# MIMXRT1021 register map
Vendor: nxp.com; File version: 1.0
CPU: CM7 r0p1, little endian, MPU, FPU, VTOR, 4 interrupt priority bits
Registers are 32-bit, read-write, reset 0x0 unless marked. A register's access mark holds for its fields unless they carry their own. Offsets are from the block's base; [hi:lo] are bit positions; 'fields as' and 'values as' point back to an identical list.

## LPI2C1 — LPI2C
Base 0x403F0000
Same registers: LPI2C2 0x403F4000, LPI2C3 0x403F8000, LPI2C4 0x403FC000
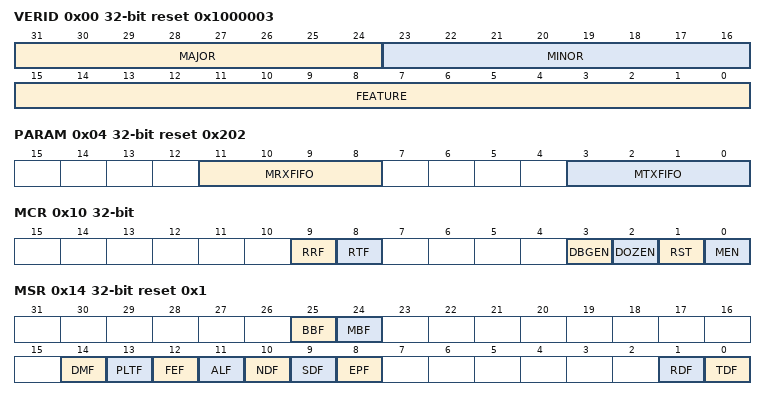
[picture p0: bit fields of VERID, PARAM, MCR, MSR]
0x00 VERID ro reset 0x1000003 — Version ID
  [31:24] MAJOR — Major Version Number
  [23:16] MINOR — Minor Version Number
  [15:0] FEATURE — Feature Specification Number
    2=MASTER_ONLY (Master only, with standard feature set); 3=MASTER_AND_SLAVE (Master and slave, with standard feature set)
0x04 PARAM ro reset 0x202 — Parameter
  [11:8] MRXFIFO — Master Receive FIFO Size
  [3:0] MTXFIFO — Master Transmit FIFO Size
0x10 MCR — Master Control
  [9] RRF — Reset Receive FIFO
    0=NO_EFFECT; 1=RESET (Receive FIFO is reset)
  [8] RTF — Reset Transmit FIFO
    0=NO_EFFECT; 1=RESET (Transmit FIFO is reset)
  [3] DBGEN — Debug Enable
    0=DISABLED (Master is disabled in debug mode); 1=ENABLED (Master is enabled in debug mode)
  [2] DOZEN — Doze mode enable
    0=ENABLED (Master is enabled in Doze mode); 1=DISABLED (Master is disabled in Doze mode)
  [1] RST — Software Reset
    0=NOT_RESET (Master logic is not reset); 1=RESET (Master logic is reset)
  [0] MEN — Master Enable
    0=DISABLED (Master logic is disabled); 1=ENABLED (Master logic is enabled)
0x14 MSR reset 0x1 — Master Status
  [25] BBF ro — Bus Busy Flag
    0=IDLE (I2C Bus is idle); 1=BUSY (I2C Bus is busy)
  [24] MBF ro — Master Busy Flag
    0=IDLE (I2C Master is idle); 1=BUSY (I2C Master is busy)
  [14] DMF write-1-clears — Data Match Flag
    0=NO_FLAG (Have not received matching data); 1=FLAG (Have received matching data)
  [13] PLTF write-1-clears — Pin Low Timeout Flag
    0=NO_FLAG (Pin low timeout has not occurred or is disabled); 1=FLAG (Pin low timeout has occurred)
  [12] FEF write-1-clears — FIFO Error Flag
    0=NO_FLAG (No error); 1=FLAG (Master sending or receiving data without a START condition)
  [11] ALF write-1-clears — Arbitration Lost Flag
    0=NO_FLAG (Master has not lost arbitration); 1=FLAG (Master has lost arbitration)
  [10] NDF write-1-clears — NACK Detect Flag
    0=NO_FLAG (Unexpected NACK was not detected); 1=FLAG (Unexpected NACK was detected)
  [9] SDF write-1-clears — STOP Detect Flag
    0=NO_FLAG (Master has not generated a STOP condition); 1=FLAG (Master has generated a STOP condition)
  [8] EPF write-1-clears — End Packet Flag
    0=NO_FLAG (Master has not generated a STOP or Repeated START condition); 1=FLAG (Master has generated a STOP or Repeated START condition)
  [1] RDF ro — Receive Data Flag
    0=DISABLED (Receive Data is not ready); 1=ENABLED (Receive data is ready)
  [0] TDF ro — Transmit Data Flag
    0=DISABLED (Transmit data is not requested); 1=ENABLED (Transmit data is requested)
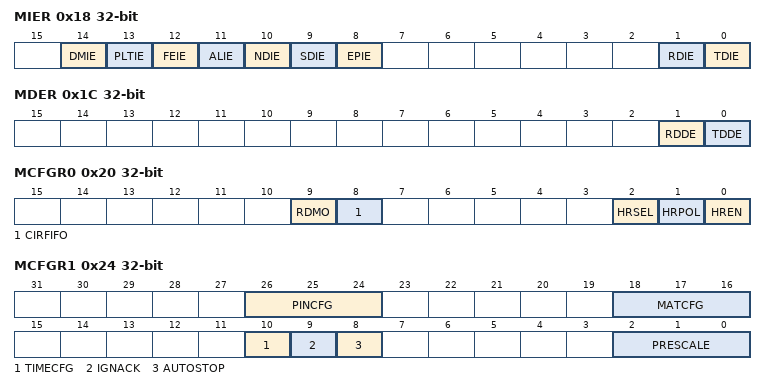
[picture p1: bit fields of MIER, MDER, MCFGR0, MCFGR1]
0x18 MIER — Master Interrupt Enable
  [14] DMIE — Data Match Interrupt Enable
    0=DISABLED; 1=ENABLED
  [13] PLTIE — Pin Low Timeout Interrupt Enable
    0=DISABLED; 1=ENABLED
  [12] FEIE — FIFO Error Interrupt Enable
    0=ENABLED; 1=DISABLED
  [11] ALIE — Arbitration Lost Interrupt Enable
    0=DISABLED; 1=ENABLED
  [10] NDIE — NACK Detect Interrupt Enable
    0=DISABLED; 1=ENABLED
  [9] SDIE — STOP Detect Interrupt Enable
    0=DISABLED; 1=ENABLED
  [8] EPIE — End Packet Interrupt Enable
    0=DISABLED; 1=ENABLED
  [1] RDIE — Receive Data Interrupt Enable
    0=DISABLED; 1=ENABLED
  [0] TDIE — Transmit Data Interrupt Enable
    0=DISABLED; 1=ENABLED
0x1C MDER — Master DMA Enable
  [1] RDDE — Receive Data DMA Enable
    0=DISABLED (DMA request is disabled); 1=ENABLED (DMA request is enabled)
  [0] TDDE — Transmit Data DMA Enable
    values as RDDE
0x20 MCFGR0 — Master Configuration 0
  [9] RDMO — Receive Data Match Only
    0=DISABLED (Received data is stored in the receive FIFO); 1=ENABLED (Received data is discarded unless the the Data Match Flag (MSR[DMF]) is set)
  [8] CIRFIFO — Circular FIFO Enable
    0=DISABLED (Circular FIFO is disabled); 1=ENABLED (Circular FIFO is enabled)
  [2] HRSEL — Host Request Select
    0=DISABLED (Host request input is pin HREQ); 1=ENABLED (Host request input is input trigger)
  [1] HRPOL — Host Request Polarity
    0=ACTIVE_LOW; 1=ACTIVE_HIGH
  [0] HREN — Host Request Enable
    0=DISABLED (Host request input is disabled); 1=ENABLED (Host request input is enabled)
0x24 MCFGR1 — Master Configuration 1
  [26:24] PINCFG — Pin Configuration
    0=OPEN_DRAIN_2_PIN (2-pin open drain mode); 1=OUTPUT_2_PIN_ONLY (2-pin output only mode (ultra-fast mode)); 2=PUSH_PULL_2_PIN (2-pin push-pull mode); 3=PUSH_PULL_4_PIN (4-pin push-pull mode); 4=OPEN_DRAIN_2_PIN_W_LPI2C_SLAVE (2-pin open drain mode with separate LPI2C slave); 5=OUTPUT_2_PIN_ONLY_W_LPI2C_SLAVE (2-pin output only mode (ultra-fast mode) with separate LPI2C slave); 6=PUSH_PULL_2_PIN_W_LPI2C_SLAVE (2-pin push-pull mode with separate LPI2C slave); 7=PUSH_PULL_4_PIN_W_LPI2C_SLAVE (4-pin push-pull mode (inverted outputs))
  [18:16] MATCFG — Match Configuration
    0=DISABLED (Match is disabled); 2=FIRST_DATA_WORD_EQUALS_MATCH0_OR_MATCH1 (Match is enabled (1st data word equals MDMR[MATCH0] OR MDMR[MATCH1])); 3=ANY_DATA_WORD_EQUALS_MATCH0_OR_MATCH1 (Match is enabled (any data word equals MDMR[MATCH0] OR MDMR[MATCH1])); 4=FIRST_DATA_WORD_MATCH0_AND_SECOND_DATA_WORD_MATCH1 (Match is enabled (1st data word equals MDMR[MATCH0] AND 2nd data word equals MDMR[MATCH1)); 5=ANY_DATA_WORD_MATCH0_NEXT_DATA_WORD_MATCH1 (Match is enabled (any data word equals MDMR[MATCH0] AND next data word equals MDMR[MATCH1)); 6=FIRST_DATA_WORD_AND_MATCH1_EQUALS_MATCH0_AND_MATCH1 (Match is enabled (1st data word AND MDMR[MATCH1] equals MDMR[MATCH0] AND MDMR[MATCH1])); 7=ANY_DATA_WORD_AND_MATCH1_EQUALS_MATCH0_AND_MATCH1 (Match is enabled (any data word AND MDMR[MATCH1] equals MDMR[MATCH0] AND MDMR[MATCH1]))
  [10] TIMECFG — Timeout Configuration
    0=IF_SCL_LOW (MSR[PLTF] sets if SCL is low for longer than the configured timeout); 1=IF_SCL_OR_SDA_LOW (MSR[PLTF] sets if either SCL or SDA is low for longer than the configured timeout)
  [9] IGNACK
    0=DISABLED (LPI2C Master receives ACK and NACK normally); 1=ENABLED (LPI2C Master treats a received NACK as if it (NACK) was an ACK)
  [8] AUTOSTOP — Automatic STOP Generation
    0=DISABLED (No effect); 1=ENABLED (STOP condition is automatically generated whenever the transmit FIFO is empty and the LPI2C master is busy)
  [2:0] PRESCALE — Prescaler
    0=DIVIDE_BY_1; 1=DIVIDE_BY_2; 2=DIVIDE_BY_4; 3=DIVIDE_BY_8; 4=DIVIDE_BY_16; 5=DIVIDE_BY_32; 6=DIVIDE_BY_64; 7=DIVIDE_BY_128
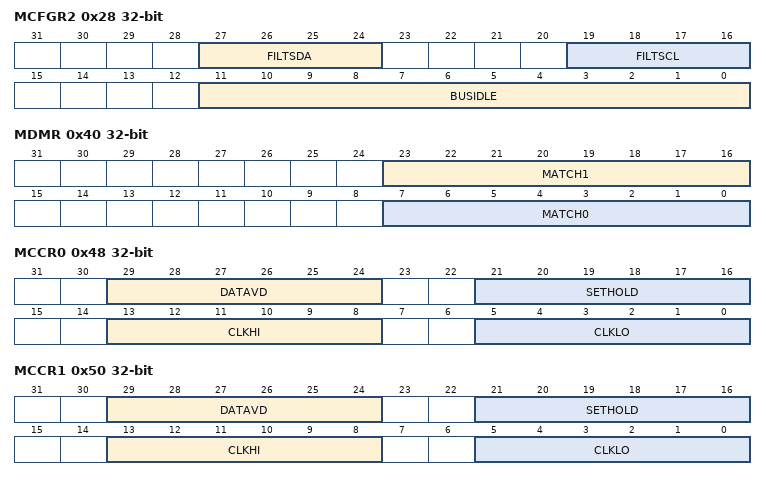
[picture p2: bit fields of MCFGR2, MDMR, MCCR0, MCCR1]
0x28 MCFGR2 — Master Configuration 2
  [27:24] FILTSDA — Glitch Filter SDA
  [19:16] FILTSCL — Glitch Filter SCL
  [11:0] BUSIDLE — Bus Idle Timeout
0x2C MCFGR3 — Master Configuration 3
  [19:8] PINLOW — Pin Low Timeout
0x40 MDMR — Master Data Match
  [23:16] MATCH1 — Match 1 Value
  [7:0] MATCH0 — Match 0 Value
0x48 MCCR0 — Master Clock Configuration 0
  [29:24] DATAVD — Data Valid Delay
  [21:16] SETHOLD — Setup Hold Delay
  [13:8] CLKHI — Clock High Period
  [5:0] CLKLO — Clock Low Period
0x50 MCCR1 — Master Clock Configuration 1
  fields as MCCR0
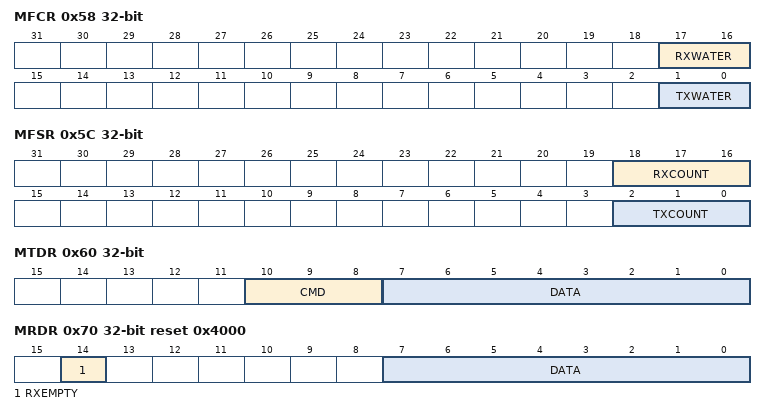
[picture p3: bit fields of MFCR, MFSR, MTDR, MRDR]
0x58 MFCR — Master FIFO Control
  [17:16] RXWATER — Receive FIFO Watermark
  [1:0] TXWATER — Transmit FIFO Watermark
0x5C MFSR ro — Master FIFO Status
  [18:16] RXCOUNT — Receive FIFO Count
  [2:0] TXCOUNT — Transmit FIFO Count
0x60 MTDR wo — Master Transmit Data
  [10:8] CMD — Command Data
    0=TRANSMIT_DATA_7_THROUGH_0 (Transmit DATA[7:0]); 1=RECEIVE_DATA_7_THROUGH_0_PLUS_ONE (Receive (DATA[7:0] + 1) bytes); 2=GENERATE_STOP_CONDITION; 3=RECEIVE_AND_DISCARD_DATA_7_THROUGH_0_PLUS_ONE (Receive and discard (DATA[7:0] + 1) bytes); 4=GENERATE_START_AND_TRANSMIT_ADDRESS_IN_DATA_7_THROUGH_0 (Generate (repeated) START and transmit address in DATA[7:0]); 5=GENERATE_START_AND_TRANSMIT_ADDRESS_IN_DATA_7_THROUGH_0_EXPECT_NACK (Generate (repeated) START and transmit address in DATA[7:0]. This transfer expects a NACK to be returned.); 6=GENERATE_START_AND_TRANSMIT_ADDRESS_IN_DATA_7_THROUGH_0_USING_HIGH_SPEED_MODE (Generate (repeated) START and transmit address in DATA[7:0] using high speed mode); 7=GENERATE_START_AND_TRANSMIT_ADDRESS_IN_DATA_7_THROUGH_0_USING_HIGH_SPEED_MODE_EXPECT_NACK (Generate (repeated) START and transmit address in DATA[7:0] using high speed mode. This transfer expects a NACK to be returned.)
  [7:0] DATA — Transmit Data
0x70 MRDR ro reset 0x4000 — Master Receive Data
  [14] RXEMPTY
    0=NOT_EMPTY (Receive FIFO is not empty); 1=EMPTY (Receive FIFO is empty)
  [7:0] DATA — Receive Data
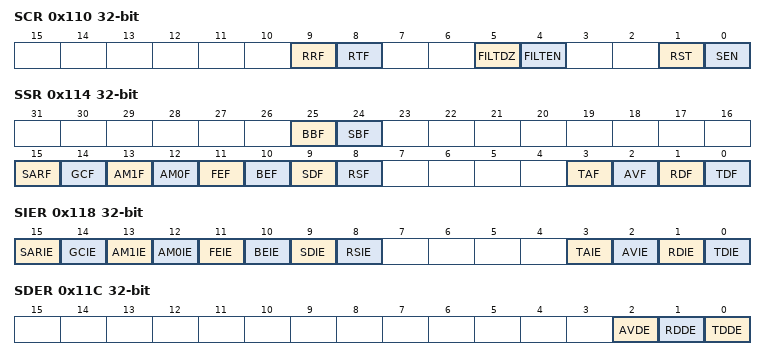
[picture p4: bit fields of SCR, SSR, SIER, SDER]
0x110 SCR — Slave Control
  [9] RRF — Reset Receive FIFO
    0=NO_EFFECT; 1=NOW_EMPTY (Receive Data Register is now empty)
  [8] RTF — Reset Transmit FIFO
    0=NO_EFFECT; 1=NOW_EMPTY (Transmit Data Register is now empty)
  [5] FILTDZ — Filter Doze Enable
    0=FILTER_ENABLED (Filter remains enabled in Doze mode); 1=FILTER_DISABLED (Filter is disabled in Doze mode)
  [4] FILTEN — Filter Enable
    0=DISABLE (Disable digital filter and output delay counter for slave mode); 1=ENABLE (Enable digital filter and output delay counter for slave mode)
  [1] RST — Software Reset
    0=NOT_RESET (Slave mode logic is not reset); 1=RESET (Slave mode logic is reset)
  [0] SEN — Slave Enable
    0=DISABLED (I2C Slave mode is disabled); 1=ENABLED (I2C Slave mode is enabled)
0x114 SSR — Slave Status
  [25] BBF ro — Bus Busy Flag
    0=IDLE (I2C Bus is idle); 1=BUSY (I2C Bus is busy)
  [24] SBF ro — Slave Busy Flag
    0=IDLE (I2C Slave is idle); 1=BUSY (I2C Slave is busy)
  [15] SARF ro — SMBus Alert Response Flag
    0=NO_FLAG (SMBus Alert Response is disabled or not detected); 1=FLAG (SMBus Alert Response is enabled and detected)
  [14] GCF ro — General Call Flag
    0=NO_FLAG (Slave has not detected the General Call Address or the General Call Address is disabled); 1=FLAG (Slave has detected the General Call Address)
  [13] AM1F ro — Address Match 1 Flag
    0=NO_FLAG (Have not received an ADDR1 or ADDR0/ADDR1 range matching address); 1=FLAG (Have received an ADDR1 or ADDR0/ADDR1 range matching address)
  [12] AM0F ro — Address Match 0 Flag
    0=NO_FLAG (Have not received an ADDR0 matching address); 1=FLAG (Have received an ADDR0 matching address)
  [11] FEF write-1-clears — FIFO Error Flag
    0=NO_FLAG (FIFO underflow or overflow was not detected); 1=FLAG (FIFO underflow or overflow was detected)
  [10] BEF write-1-clears — Bit Error Flag
    0=NO_FLAG (Slave has not detected a bit error); 1=FLAG (Slave has detected a bit error)
  [9] SDF write-1-clears — STOP Detect Flag
    0=NO_FLAG (Slave has not detected a STOP condition); 1=FLAG (Slave has detected a STOP condition)
  [8] RSF write-1-clears — Repeated Start Flag
    0=NO_FLAG (Slave has not detected a Repeated START condition); 1=FLAG (Slave has detected a Repeated START condition)
  [3] TAF ro — Transmit ACK Flag
    0=NOT_REQUIRED (Transmit ACK/NACK is not required); 1=REQUIRED (Transmit ACK/NACK is required)
  [2] AVF ro — Address Valid Flag
    0=NOT_VALID (Address Status Register is not valid); 1=VALID (Address Status Register is valid)
  [1] RDF ro — Receive Data Flag
    0=NOT_READY (Receive data is not ready); 1=READY (Receive data is ready)
  [0] TDF ro — Transmit Data Flag
    0=NO_FLAG (Transmit data not requested); 1=FLAG (Transmit data is requested)
0x118 SIER — Slave Interrupt Enable
  [all] fields
    0=DISABLED; 1=ENABLED
  [15] SARIE — SMBus Alert Response Interrupt Enable
  [14] GCIE — General Call Interrupt Enable
  [13] AM1IE — Address Match 1 Interrupt Enable
  [12] AM0IE — Address Match 0 Interrupt Enable
  [11] FEIE — FIFO Error Interrupt Enable
  [10] BEIE — Bit Error Interrupt Enable
  [9] SDIE — STOP Detect Interrupt Enable
  [8] RSIE — Repeated Start Interrupt Enable
  [3] TAIE — Transmit ACK Interrupt Enable
  [2] AVIE — Address Valid Interrupt Enable
  [1] RDIE — Receive Data Interrupt Enable
  [0] TDIE — Transmit Data Interrupt Enable
0x11C SDER — Slave DMA Enable
  [all] fields
    values as MDER.RDDE
  [2] AVDE — Address Valid DMA Enable
  [1] RDDE — Receive Data DMA Enable
  [0] TDDE — Transmit Data DMA Enable
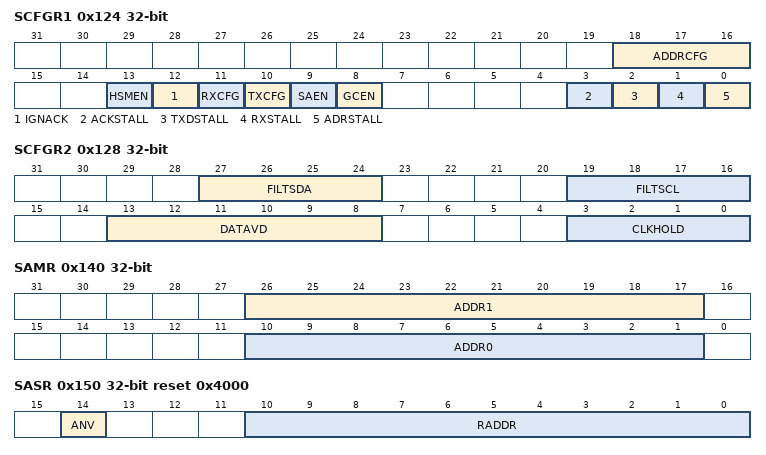
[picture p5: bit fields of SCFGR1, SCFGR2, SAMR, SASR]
0x124 SCFGR1 — Slave Configuration 1
  [18:16] ADDRCFG — Address Configuration
    0=ADDRESS_MATCH0_7_BIT; 1=ADDRESS_MATCH0_10_BIT; 2=ADDRESS_MATCH0_7_BIT_OR_ADDRESS_MATCH1_7_BIT; 3=ADDRESS_MATCH0_10_BIT_OR_ADDRESS_MATCH1_10_BIT; 4=ADDRESS_MATCH0_7_BIT_OR_ADDRESS_MATCH1_10_BIT; 5=ADDRESS_MATCH0_10_BIT_OR_ADDRESS_MATCH1_7_BIT; 6=FROM_ADDRESS_MATCH0_7_BIT_TO_ADDRESS_MATCH1_7_BIT; 7=FROM_ADDRESS_MATCH0_10_BIT_TO_ADDRESS_MATCH1_10_BIT
  [13] HSMEN — High Speed Mode Enable
    0=DISABLED (Disables detection of HS-mode master code); 1=ENABLED (Enables detection of HS-mode master code)
  [12] IGNACK — Ignore NACK
    0=ENDS_TRANSFER_ON_NACK (Slave ends transfer when NACK is detected); 1=DOES_NOT_END_TRANSFER_ON_NACK (Slave does not end transfer when NACK detected)
  [11] RXCFG — Receive Data Configuration
    0=RETURNS_RECEIVED_DATA_AND_CLEARS_RX_DATA_FLAG (Reading the Receive Data register returns received data and clears the Receive Data flag (MSR[RDF]).); 1=WHEN_ADDRESS_VALID_FLAG_SET_RETURNS_ADDRESS_STATUS_AND_CLEARS_ADDRESS_VALID_FLAG (Reading the Receive Data register when the Address Valid flag (SSR[AVF])is set, returns the Address Status register and clear the Address Valid flag. Reading the Receive Data register when the Address Valid flag is clear, returns received data and clears the Receive Data flag (MSR[RDF]).)
  [10] TXCFG — Transmit Flag Configuration
    0=ASSERTS_DURING_SLAVE_TRANSMIT_TRANSFER_WHEN_TX_DATA_EMPTY (Transmit Data Flag only asserts during a slave-transmit transfer when the Transmit Data register is empty); 1=ASSERTS_WHEN_TX_DATA_EMPTY (Transmit Data Flag asserts whenever the Transmit Data register is empty)
  [9] SAEN — SMBus Alert Enable
    0=DISABLE (Disables match on SMBus Alert); 1=ENABLE (Enables match on SMBus Alert)
  [8] GCEN — General Call Enable
    0=DISABLED (General Call address is disabled); 1=ENABLED (General Call address is enabled)
  [3] ACKSTALL — ACK SCL Stall
    0=DISABLED (Clock stretching is disabled); 1=ENABLED (Clock stretching is enabled)
  [2] TXDSTALL — TX Data SCL Stall
    values as ACKSTALL
  [1] RXSTALL — RX SCL Stall
    values as ACKSTALL
  [0] ADRSTALL — Address SCL Stall
    values as ACKSTALL
0x128 SCFGR2 — Slave Configuration 2
  [27:24] FILTSDA — Glitch Filter SDA
  [19:16] FILTSCL — Glitch Filter SCL
  [13:8] DATAVD — Data Valid Delay
  [3:0] CLKHOLD — Clock Hold Time
0x140 SAMR — Slave Address Match
  [26:17] ADDR1 — Address 1 Value
  [10:1] ADDR0 — Address 0 Value
0x150 SASR ro reset 0x4000 — Slave Address Status
  [14] ANV — Address Not Valid
    0=VALID (Received Address (RADDR) is valid); 1=NOT_VALID (Received Address (RADDR) is not valid)
  [10:0] RADDR — Received Address
0x154 STAR — Slave Transmit ACK
  [0] TXNACK — Transmit NACK
    0=TRANSMIT_ACK (Write a Transmit ACK for each received word); 1=TRANSMIT_NACK (Write a Transmit NACK for each received word)
0x160 STDR wo — Slave Transmit Data
  [7:0] DATA — Transmit Data
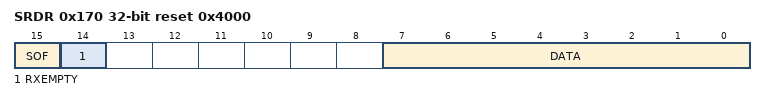
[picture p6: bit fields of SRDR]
0x170 SRDR ro reset 0x4000 — Slave Receive Data
  [15] SOF — Start Of Frame
    0=NOT_FIRST_DATA_WORD (Indicates this is not the first data word since a (repeated) START or STOP condition); 1=FIRST_DATA_WORD (Indicates this is the first data word since a (repeated) START or STOP condition)
  [14] RXEMPTY
    0=NOT_EMPTY (The Receive Data Register is not empty); 1=EMPTY (The Receive Data Register is empty)
  [7:0] DATA — Receive Data
